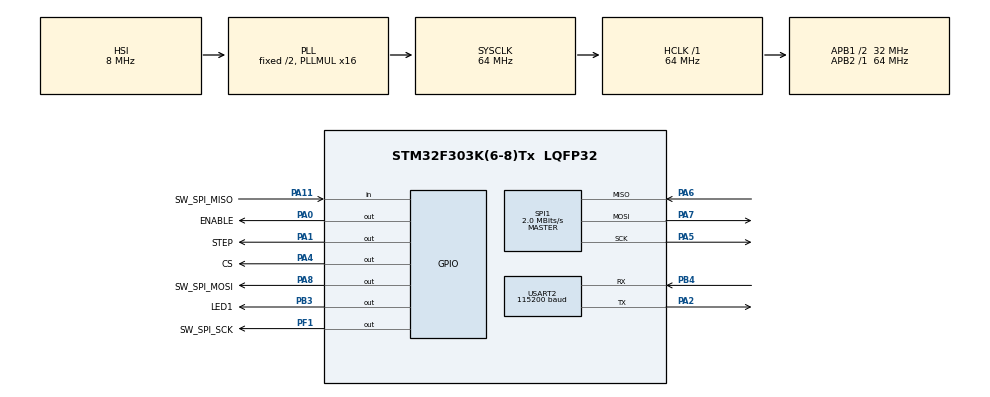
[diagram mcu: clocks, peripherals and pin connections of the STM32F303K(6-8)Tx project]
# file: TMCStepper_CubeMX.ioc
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Mcu.Family=STM32F3
Mcu.Name=STM32F303K(6-8)Tx
Mcu.Package=LQFP32
NVIC.PriorityGroup=NVIC_PRIORITYGROUP_4
PA0.GPIO_Label=ENABLE
PA0.Signal=GPIO_Output
PA1.GPIO_Label=STEP
PA1.Signal=GPIO_Output
PA11.GPIO_Label=SW_SPI_MISO
PA11.Signal=GPIO_Input
PA13.GPIO_Label=SWDIO
PA13.Mode=Serial_Wire
PA13.Signal=SYS_JTMS-SWDIO
PA14.GPIO_Label=SWCLK
PA14.Mode=Serial_Wire
PA14.Signal=SYS_JTCK-SWCLK
PA2.Mode=Asynchronous
PA2.Signal=USART2_TX
PA4.GPIO_Label=CS
PA4.PinState=GPIO_PIN_SET
PA4.Signal=GPIO_Output
PA5.Mode=Full_Duplex_Master
PA5.Signal=SPI1_SCK
PA6.Mode=Full_Duplex_Master
PA6.Signal=SPI1_MISO
PA7.Mode=Full_Duplex_Master
PA7.Signal=SPI1_MOSI
PA8.GPIO_Label=SW_SPI_MOSI
PA8.GPIO_Speed=GPIO_SPEED_FREQ_HIGH
PA8.Signal=GPIO_Output
PB3.GPIO_Label=LED1
PB3.Signal=GPIO_Output
PB4.Mode=Asynchronous
PB4.Signal=USART2_RX
PF0\ /\ OSC_IN.GPIO_Label=MCO
PF0\ /\ OSC_IN.Signal=RCC_OSC_IN
PF1\ /\ OSC_OUT.GPIO_Label=SW_SPI_SCK
PF1\ /\ OSC_OUT.GPIO_Speed=GPIO_SPEED_FREQ_HIGH
PF1\ /\ OSC_OUT.Signal=GPIO_Output
ProjectManager.HeapSize=0x200
ProjectManager.StackSize=0x400
ProjectManager.TargetToolchain=STM32CubeIDE
RCC.AHBFreq_Value=64000000
RCC.APB1CLKDivider=RCC_HCLK_DIV2
RCC.APB1Freq_Value=32000000
RCC.APB1TimFreq_Value=64000000
RCC.APB2Freq_Value=64000000
RCC.APB2TimFreq_Value=64000000
RCC.CortexFreq_Value=64000000
RCC.HCLKFreq_Value=64000000
RCC.HSE_VALUE=8000000
RCC.HSI_VALUE=8000000
RCC.PLLMUL=RCC_PLL_MUL16
RCC.SYSCLKFreq_VALUE=64000000
RCC.SYSCLKSourceVirtual=RCC_SYSCLKSOURCE_PLLCLK
SPI1.BaudRatePrescaler=SPI_BAUDRATEPRESCALER_32
SPI1.CLKPhase=SPI_PHASE_2EDGE
SPI1.CLKPolarity=SPI_POLARITY_HIGH
SPI1.CalculateBaudRate=2.0 MBits/s
SPI1.DataSize=SPI_DATASIZE_8BIT
SPI1.Direction=SPI_DIRECTION_2LINES
SPI1.Mode=SPI_MODE_MASTER
SPI1.VirtualType=VM_MASTER
USART2.BaudRate=115200
USART2.OverrunDisableParam=ADVFEATURE_OVERRUN_DISABLE
USART2.VirtualMode-Asynchronous=VM_ASYNC
board=NUCLEO-F303K8

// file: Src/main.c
/* USER CODE BEGIN Header */
/**
  ******************************************************************************
  * @file           : main.c
  * @brief          : Main program body
  ******************************************************************************
  * @attention
  *
  * <h2><center>&copy; Copyright (c) 2020 STMicroelectronics.
  * All rights reserved.</center></h2>
  *
  * This software component is licensed by ST under BSD 3-Clause license,
  * the "License"; You may not use this file except in compliance with the
  * License. You may obtain a copy of the License at:
  *                        opensource.org/licenses/BSD-3-Clause
  *
  ******************************************************************************
  */
/* USER CODE END Header */
#include "main.h"
#include "spi.h"
#include "usart.h"
#include "gpio.h"

void SystemClock_Config(void);
/* USER CODE BEGIN PFP */
void initDriver();
void runMotor();
/* USER CODE END PFP */

int main(void)
{

  /* MCU Configuration--------------------------------------------------------*/

  /* Reset of all peripherals, Initializes the Flash interface and the Systick. */
  HAL_Init();

  /* Configure the system clock */
  SystemClock_Config();

  /* Initialize all configured peripherals */
  MX_GPIO_Init();
  MX_USART2_UART_Init();
  MX_SPI1_Init();
  /* USER CODE BEGIN 2 */
  initDriver();
  /* USER CODE END 2 */

  /* Infinite loop */
  while (1)
  {

    /* USER CODE BEGIN 3 */
    runMotor();
  }
  /* USER CODE END 3 */
}

void SystemClock_Config(void)
{
  RCC_OscInitTypeDef RCC_OscInitStruct = {0};
  RCC_ClkInitTypeDef RCC_ClkInitStruct = {0};

  /** Initializes the RCC Oscillators according to the specified parameters
  * in the RCC_OscInitTypeDef structure.
  */
  RCC_OscInitStruct.OscillatorType = RCC_OSCILLATORTYPE_HSI;
  RCC_OscInitStruct.HSIState = RCC_HSI_ON;
  RCC_OscInitStruct.HSICalibrationValue = RCC_HSICALIBRATION_DEFAULT;
  RCC_OscInitStruct.PLL.PLLState = RCC_PLL_ON;
  RCC_OscInitStruct.PLL.PLLSource = RCC_PLLSOURCE_HSI;
  RCC_OscInitStruct.PLL.PLLMUL = RCC_PLL_MUL16;
  if (HAL_RCC_OscConfig(&RCC_OscInitStruct) != HAL_OK)
  {
    Error_Handler();
  }
  /** Initializes the CPU, AHB and APB buses clocks
  */
  RCC_ClkInitStruct.ClockType = RCC_CLOCKTYPE_HCLK|RCC_CLOCKTYPE_SYSCLK
                              |RCC_CLOCKTYPE_PCLK1|RCC_CLOCKTYPE_PCLK2;
  RCC_ClkInitStruct.SYSCLKSource = RCC_SYSCLKSOURCE_PLLCLK;
  RCC_ClkInitStruct.AHBCLKDivider = RCC_SYSCLK_DIV1;
  RCC_ClkInitStruct.APB1CLKDivider = RCC_HCLK_DIV2;
  RCC_ClkInitStruct.APB2CLKDivider = RCC_HCLK_DIV1;

  if (HAL_RCC_ClockConfig(&RCC_ClkInitStruct, FLASH_LATENCY_2) != HAL_OK)
  {
    Error_Handler();
  }
}

void Error_Handler(void)
{
}

/************************ (C) COPYRIGHT STMicroelectronics *****END OF FILE****/
